# cslr_edma3cc register map
Vendor: Texas Instruments
Peripheral module from a debugger description file.
Registers are 32-bit, read-write, reset 0x0 unless marked. A register's access mark holds for its fields unless they carry their own. Offsets are as the file gives them; lines under a group give offsets from that group; [hi:lo] are bit positions; {n}, {i} and the like mark numbered series; 'fields as' and 'values as' point back to an identical list; <NAME> marks a mode.

## EDMA3CC — Enhanced DMA Channel Controller Module.
0x00 PID ro — Peripheral Revision
  [31:0] REG
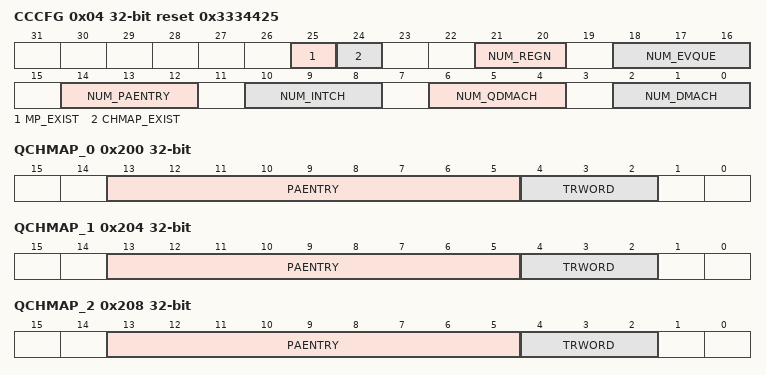
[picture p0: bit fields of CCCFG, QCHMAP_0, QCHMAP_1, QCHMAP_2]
0x04 CCCFG ro reset 0x3334425 — CC Configuration
  [25] MP_EXIST — Memory Protection Existence
    1=INCLUDED (Memory protection logic included)
  [24] CHMAP_EXIST — Channel Mapping Existence
    1=INCLUDED (Channel mapping logic included)
  [21:20] NUM_REGN — Number of MP and Shadow regions
    3=8 Regions
  [18:16] NUM_EVQUE — Number of Queues/Number of TCs
    3=4 TC/Event Queue
  [14:12] NUM_PAENTRY — Number of PaRAM entries
    4=256 Entries
  [10:8] NUM_INTCH — Number of Interrupt Channels
    4=64 Interrupt Channels
  [6:4] NUM_QDMACH — Number of QDMA Channels
    2=4 QDMA Channels
  [2:0] NUM_DMACH — Number of DMA Channels
    5=64 DMA Channels
0x100 DCHMAP_0 access per field — DMA Channel Mapping to PaRAM{DCHMAP}
  [13:5] PAENTRY rw — Points to the PaRAM Entry number for the DMA Channel N
0x104 DCHMAP_1 access per field — DMA Channel Mapping to PaRAM{DCHMAP}
  fields as DCHMAP_0
0x108 DCHMAP_2 access per field — DMA Channel Mapping to PaRAM{DCHMAP}
  fields as DCHMAP_0
0x10C DCHMAP_3 access per field — DMA Channel Mapping to PaRAM{DCHMAP}
  fields as DCHMAP_0
0x110 DCHMAP_4 access per field — DMA Channel Mapping to PaRAM{DCHMAP}
  fields as DCHMAP_0
0x114 DCHMAP_5 access per field — DMA Channel Mapping to PaRAM{DCHMAP}
  fields as DCHMAP_0
0x118 DCHMAP_6 access per field — DMA Channel Mapping to PaRAM{DCHMAP}
  fields as DCHMAP_0
0x11C DCHMAP_7 access per field — DMA Channel Mapping to PaRAM{DCHMAP}
  fields as DCHMAP_0
0x120 DCHMAP_8 access per field — DMA Channel Mapping to PaRAM{DCHMAP}
  fields as DCHMAP_0
0x124 DCHMAP_9 access per field — DMA Channel Mapping to PaRAM{DCHMAP}
  fields as DCHMAP_0
0x128 DCHMAP_10 access per field — DMA Channel Mapping to PaRAM{DCHMAP}
  fields as DCHMAP_0
0x12C DCHMAP_11 access per field — DMA Channel Mapping to PaRAM{DCHMAP}
  fields as DCHMAP_0
0x130 DCHMAP_12 access per field — DMA Channel Mapping to PaRAM{DCHMAP}
  fields as DCHMAP_0
0x134 DCHMAP_13 access per field — DMA Channel Mapping to PaRAM{DCHMAP}
  fields as DCHMAP_0
0x138 DCHMAP_14 access per field — DMA Channel Mapping to PaRAM{DCHMAP}
  fields as DCHMAP_0
0x13C DCHMAP_15 access per field — DMA Channel Mapping to PaRAM{DCHMAP}
  fields as DCHMAP_0
0x140 DCHMAP_16 access per field — DMA Channel Mapping to PaRAM{DCHMAP}
  fields as DCHMAP_0
0x144 DCHMAP_17 access per field — DMA Channel Mapping to PaRAM{DCHMAP}
  fields as DCHMAP_0
0x148 DCHMAP_18 access per field — DMA Channel Mapping to PaRAM{DCHMAP}
  fields as DCHMAP_0
0x14C DCHMAP_19 access per field — DMA Channel Mapping to PaRAM{DCHMAP}
  fields as DCHMAP_0
0x150 DCHMAP_20 access per field — DMA Channel Mapping to PaRAM{DCHMAP}
  fields as DCHMAP_0
0x154 DCHMAP_21 access per field — DMA Channel Mapping to PaRAM{DCHMAP}
  fields as DCHMAP_0
0x158 DCHMAP_22 access per field — DMA Channel Mapping to PaRAM{DCHMAP}
  fields as DCHMAP_0
0x15C DCHMAP_23 access per field — DMA Channel Mapping to PaRAM{DCHMAP}
  fields as DCHMAP_0
0x160 DCHMAP_24 access per field — DMA Channel Mapping to PaRAM{DCHMAP}
  fields as DCHMAP_0
0x164 DCHMAP_25 access per field — DMA Channel Mapping to PaRAM{DCHMAP}
  fields as DCHMAP_0
0x168 DCHMAP_26 access per field — DMA Channel Mapping to PaRAM{DCHMAP}
  fields as DCHMAP_0
0x16C DCHMAP_27 access per field — DMA Channel Mapping to PaRAM{DCHMAP}
  fields as DCHMAP_0
0x170 DCHMAP_28 access per field — DMA Channel Mapping to PaRAM{DCHMAP}
  fields as DCHMAP_0
0x174 DCHMAP_29 access per field — DMA Channel Mapping to PaRAM{DCHMAP}
  fields as DCHMAP_0
0x178 DCHMAP_30 access per field — DMA Channel Mapping to PaRAM{DCHMAP}
  fields as DCHMAP_0
0x17C DCHMAP_31 access per field — DMA Channel Mapping to PaRAM{DCHMAP}
  fields as DCHMAP_0
0x180 DCHMAP_32 access per field — DMA Channel Mapping to PaRAM{DCHMAP}
  fields as DCHMAP_0
0x184 DCHMAP_33 access per field — DMA Channel Mapping to PaRAM{DCHMAP}
  fields as DCHMAP_0
0x188 DCHMAP_34 access per field — DMA Channel Mapping to PaRAM{DCHMAP}
  fields as DCHMAP_0
0x18C DCHMAP_35 access per field — DMA Channel Mapping to PaRAM{DCHMAP}
  fields as DCHMAP_0
0x190 DCHMAP_36 access per field — DMA Channel Mapping to PaRAM{DCHMAP}
  fields as DCHMAP_0
0x194 DCHMAP_37 access per field — DMA Channel Mapping to PaRAM{DCHMAP}
  fields as DCHMAP_0
0x198 DCHMAP_38 access per field — DMA Channel Mapping to PaRAM{DCHMAP}
  fields as DCHMAP_0
0x19C DCHMAP_39 access per field — DMA Channel Mapping to PaRAM{DCHMAP}
  fields as DCHMAP_0
0x1A0 DCHMAP_40 access per field — DMA Channel Mapping to PaRAM{DCHMAP}
  fields as DCHMAP_0
0x1A4 DCHMAP_41 access per field — DMA Channel Mapping to PaRAM{DCHMAP}
  fields as DCHMAP_0
0x1A8 DCHMAP_42 access per field — DMA Channel Mapping to PaRAM{DCHMAP}
  fields as DCHMAP_0
0x1AC DCHMAP_43 access per field — DMA Channel Mapping to PaRAM{DCHMAP}
  fields as DCHMAP_0
0x1B0 DCHMAP_44 access per field — DMA Channel Mapping to PaRAM{DCHMAP}
  fields as DCHMAP_0
0x1B4 DCHMAP_45 access per field — DMA Channel Mapping to PaRAM{DCHMAP}
  fields as DCHMAP_0
0x1B8 DCHMAP_46 access per field — DMA Channel Mapping to PaRAM{DCHMAP}
  fields as DCHMAP_0
0x1BC DCHMAP_47 access per field — DMA Channel Mapping to PaRAM{DCHMAP}
  fields as DCHMAP_0
0x1C0 DCHMAP_48 access per field — DMA Channel Mapping to PaRAM{DCHMAP}
  fields as DCHMAP_0
0x1C4 DCHMAP_49 access per field — DMA Channel Mapping to PaRAM{DCHMAP}
  fields as DCHMAP_0
0x1C8 DCHMAP_50 access per field — DMA Channel Mapping to PaRAM{DCHMAP}
  fields as DCHMAP_0
0x1CC DCHMAP_51 access per field — DMA Channel Mapping to PaRAM{DCHMAP}
  fields as DCHMAP_0
0x1D0 DCHMAP_52 access per field — DMA Channel Mapping to PaRAM{DCHMAP}
  fields as DCHMAP_0
0x1D4 DCHMAP_53 access per field — DMA Channel Mapping to PaRAM{DCHMAP}
  fields as DCHMAP_0
0x1D8 DCHMAP_54 access per field — DMA Channel Mapping to PaRAM{DCHMAP}
  fields as DCHMAP_0
0x1DC DCHMAP_55 access per field — DMA Channel Mapping to PaRAM{DCHMAP}
  fields as DCHMAP_0
0x1E0 DCHMAP_56 access per field — DMA Channel Mapping to PaRAM{DCHMAP}
  fields as DCHMAP_0
0x1E4 DCHMAP_57 access per field — DMA Channel Mapping to PaRAM{DCHMAP}
  fields as DCHMAP_0
0x1E8 DCHMAP_58 access per field — DMA Channel Mapping to PaRAM{DCHMAP}
  fields as DCHMAP_0
0x1EC DCHMAP_59 access per field — DMA Channel Mapping to PaRAM{DCHMAP}
  fields as DCHMAP_0
0x1F0 DCHMAP_60 access per field — DMA Channel Mapping to PaRAM{DCHMAP}
  fields as DCHMAP_0
0x1F4 DCHMAP_61 access per field — DMA Channel Mapping to PaRAM{DCHMAP}
  fields as DCHMAP_0
0x1F8 DCHMAP_62 access per field — DMA Channel Mapping to PaRAM{DCHMAP}
  fields as DCHMAP_0
0x1FC DCHMAP_63 access per field — DMA Channel Mapping to PaRAM{DCHMAP}
  fields as DCHMAP_0
0x200 QCHMAP_0 access per field — QDMA Channel Mapping to PaRAM{QCHMAP}
  [13:5] PAENTRY rw — Points to the PaRAM Entry number for the DMA Channel N
  [4:2] TRWORD rw — Points to the specific trigger word of the PaRAM entry defined by PAENTRY
0x204 QCHMAP_1 access per field — QDMA Channel Mapping to PaRAM{QCHMAP}
  fields as QCHMAP_0
0x208 QCHMAP_2 access per field — QDMA Channel Mapping to PaRAM{QCHMAP}
  fields as QCHMAP_0
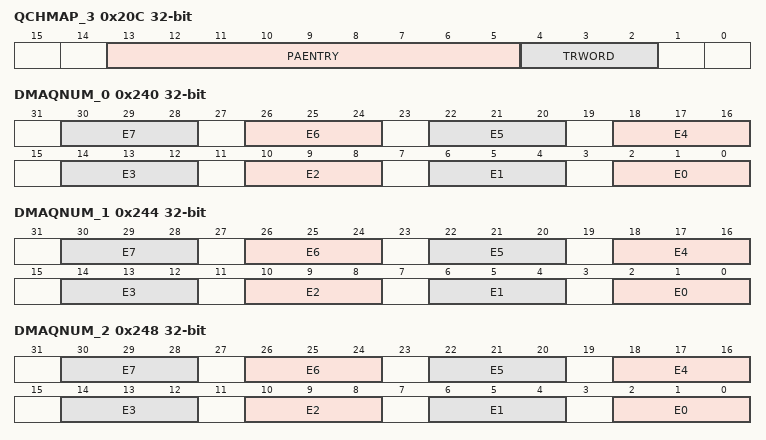
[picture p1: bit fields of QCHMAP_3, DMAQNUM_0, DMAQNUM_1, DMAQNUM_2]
0x20C QCHMAP_3 access per field — QDMA Channel Mapping to PaRAM{QCHMAP}
  fields as QCHMAP_0
0x240 DMAQNUM_0 access per field — DMA Queue Number{DMAQNUM}
  [4n+2:4n] E{n} rw (n=0..7) — Event number = (ArrayIndex * 8) + {n}
0x244 DMAQNUM_1 access per field — DMA Queue Number{DMAQNUM}
  [4n+2:4n] E{n} rw (n=0..7) — Event number = (ArrayIndex * 8) + {n}
0x248 DMAQNUM_2 access per field — DMA Queue Number{DMAQNUM}
  [4n+2:4n] E{n} rw (n=0..7) — Event number = (ArrayIndex * 8) + {n}
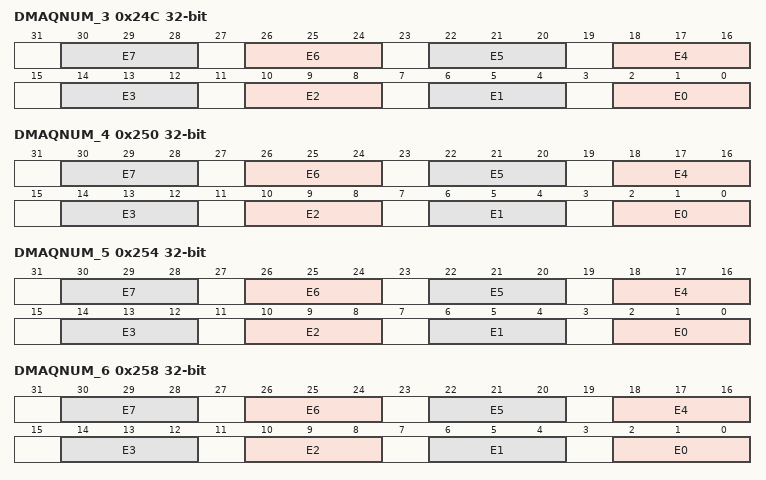
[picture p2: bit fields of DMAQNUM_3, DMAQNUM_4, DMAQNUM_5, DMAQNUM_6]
0x24C DMAQNUM_3 access per field — DMA Queue Number{DMAQNUM}
  [4n+2:4n] E{n} rw (n=0..7) — Event number = (ArrayIndex * 8) + {n}
0x250 DMAQNUM_4 access per field — DMA Queue Number{DMAQNUM}
  [4n+2:4n] E{n} rw (n=0..7) — Event number = (ArrayIndex * 8) + {n}
0x254 DMAQNUM_5 access per field — DMA Queue Number{DMAQNUM}
  [4n+2:4n] E{n} rw (n=0..7) — Event number = (ArrayIndex * 8) + {n}
0x258 DMAQNUM_6 access per field — DMA Queue Number{DMAQNUM}
  [4n+2:4n] E{n} rw (n=0..7) — Event number = (ArrayIndex * 8) + {n}
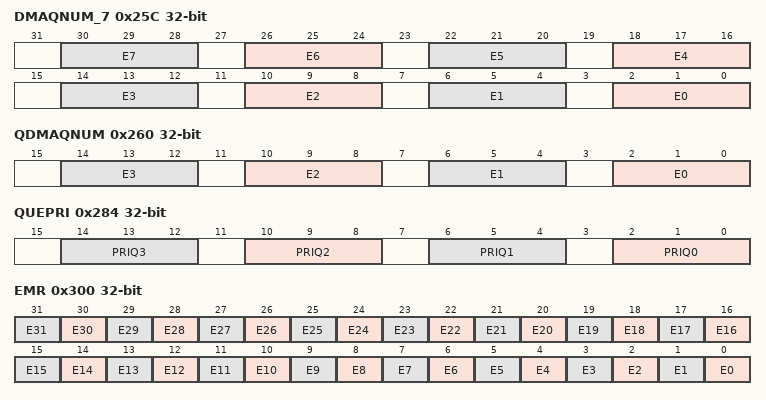
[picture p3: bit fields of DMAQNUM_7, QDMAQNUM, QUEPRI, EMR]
0x25C DMAQNUM_7 access per field — DMA Queue Number{DMAQNUM}
  [4n+2:4n] E{n} rw (n=0..7) — Event number = (ArrayIndex * 8) + {n}
0x260 QDMAQNUM access per field — QDMA Queue Number
  [4n+2:4n] E{n} rw (n=0..3) — Event number {n}
0x284 QUEPRI access per field — Queue Priority
  [4n+2:4n] PRIQ{n} rw (n=0..3) — Priority level for Queue {n}
0x300 EMR ro — Event Miss Register
  [n] E{n} (n=0..31) — Event missed number {n}
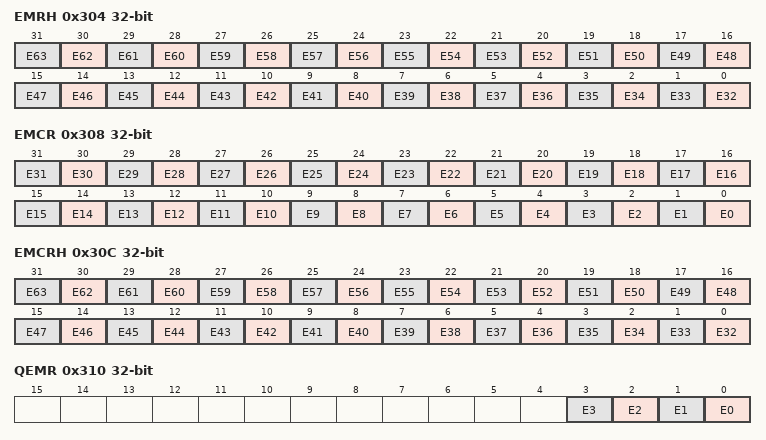
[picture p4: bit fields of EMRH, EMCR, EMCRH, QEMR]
0x304 EMRH ro — Event Miss Register High
  [n-32] E{n} (n=32..63) — Event missed number {n}
0x308 EMCR wo — Event Miss Clear Register
  [all] fields
    1=CLEAR
  [n] E{n} (n=0..31) — Event missed number {n}
0x30C EMCRH wo — Event Miss Clear Register High
  [all] fields
    1=CLEAR
  [n-32] E{n} (n=32..63) — Event missed number {n}
0x310 QEMR ro — QDMA Event Miss Register
  [n] E{n} (n=0..3) — Event miss event {n}
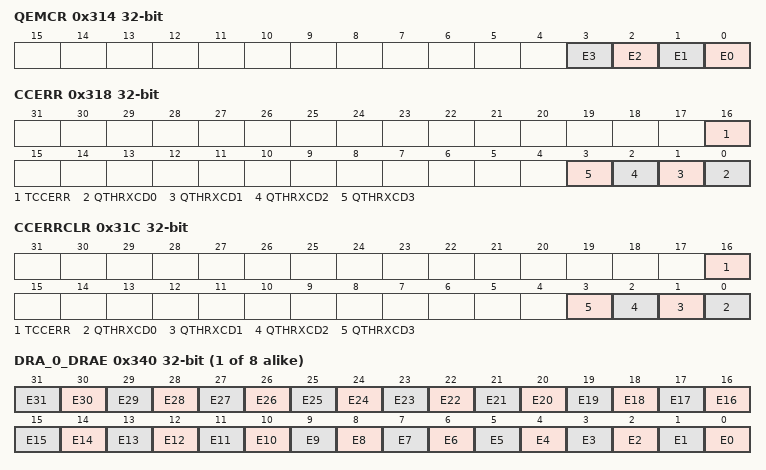
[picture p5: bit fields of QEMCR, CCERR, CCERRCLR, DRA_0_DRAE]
0x314 QEMCR wo — QDMA Event Miss Register
  [all] fields
    1=CLEAR
  [n] E{n} (n=0..3) — Event miss event {n}
0x318 CCERR ro — CC Error Register
  [16] TCCERR — Transfer completion code error
  [n] QTHRXCD{n} (n=0..3) — Queue Threshold Error for Queue {n}
0x31C CCERRCLR wo — CC Error Clear Register
  [all] fields
    1=CLEAR
  [16] TCCERR — Transfer completion code error
  [n] QTHRXCD{n} (n=0..3) — Queue Threshold Error for Queue {n}
0x320 EEVAL access per field — Error Evaluation Register
  [0] EVAL wo — Error interrupt Evaluate
    1=EVAL (Error Interrupt Evaluate)
{0x340+8i} DRA_{i}_DRAE (i=0..7) — DMA Region Access Enable
  [n] E{n} (n=0..31) — Event missed number {n}
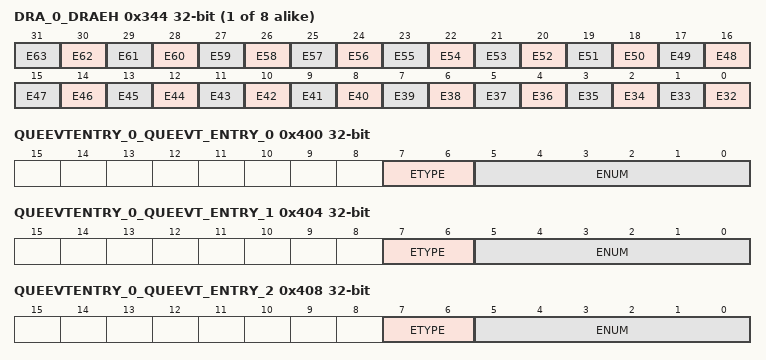
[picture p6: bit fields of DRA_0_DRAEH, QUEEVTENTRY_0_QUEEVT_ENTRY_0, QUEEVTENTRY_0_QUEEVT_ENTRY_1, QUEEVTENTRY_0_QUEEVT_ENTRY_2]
{0x344+8i} DRA_{i}_DRAEH (i=0..7) — DMA Region Access Enable High
  [n-32] E{n} (n=32..63) — Event missed number {n}
0x380 QRAE_0 access not given — QDMA Region Access Enable{QRAE}
  [7] E{n} rw (n=0..7) — QDMA Register bit {n}
  [6:0] Reserved — (access N)
0x384 QRAE_1 access not given — QDMA Region Access Enable{QRAE}
  fields as QRAE_0
0x388 QRAE_2 access not given — QDMA Region Access Enable{QRAE}
  fields as QRAE_0
0x38C QRAE_3 access not given — QDMA Region Access Enable{QRAE}
  fields as QRAE_0
0x390 QRAE_4 access not given — QDMA Region Access Enable{QRAE}
  fields as QRAE_0
0x394 QRAE_5 access not given — QDMA Region Access Enable{QRAE}
  fields as QRAE_0
0x398 QRAE_6 access not given — QDMA Region Access Enable{QRAE}
  fields as QRAE_0
0x39C QRAE_7 access not given — QDMA Region Access Enable{QRAE}
  fields as QRAE_0
0x400 QUEEVTENTRY_0_QUEEVT_ENTRY_0 ro — Event Entry{EVT_ENTRY}
  [7:6] ETYPE — Event Type
    0=EVENT (Event Triggered via ER); 1=MANUAL (Manual Triggered via ESR); 2=CHAIN (Chain Triggered via CER); 3=AUTO (Auto Triggered via QER)
  [5:0] ENUM — Event Number (0-63)/(0-3)
0x404 QUEEVTENTRY_0_QUEEVT_ENTRY_1 ro — Event Entry{EVT_ENTRY}
  fields as QUEEVTENTRY_0_QUEEVT_ENTRY_0
0x408 QUEEVTENTRY_0_QUEEVT_ENTRY_2 ro — Event Entry{EVT_ENTRY}
  fields as QUEEVTENTRY_0_QUEEVT_ENTRY_0
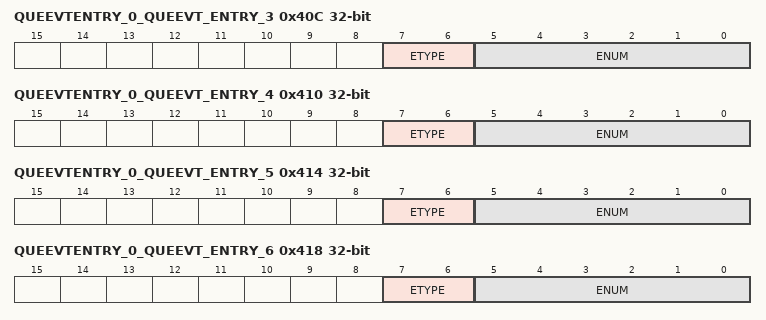
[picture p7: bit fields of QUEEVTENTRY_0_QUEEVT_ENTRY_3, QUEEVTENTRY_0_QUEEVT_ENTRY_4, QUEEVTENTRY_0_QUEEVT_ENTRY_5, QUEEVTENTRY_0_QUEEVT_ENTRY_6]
0x40C QUEEVTENTRY_0_QUEEVT_ENTRY_3 ro — Event Entry{EVT_ENTRY}
  fields as QUEEVTENTRY_0_QUEEVT_ENTRY_0
0x410 QUEEVTENTRY_0_QUEEVT_ENTRY_4 ro — Event Entry{EVT_ENTRY}
  fields as QUEEVTENTRY_0_QUEEVT_ENTRY_0
0x414 QUEEVTENTRY_0_QUEEVT_ENTRY_5 ro — Event Entry{EVT_ENTRY}
  fields as QUEEVTENTRY_0_QUEEVT_ENTRY_0
0x418 QUEEVTENTRY_0_QUEEVT_ENTRY_6 ro — Event Entry{EVT_ENTRY}
  fields as QUEEVTENTRY_0_QUEEVT_ENTRY_0
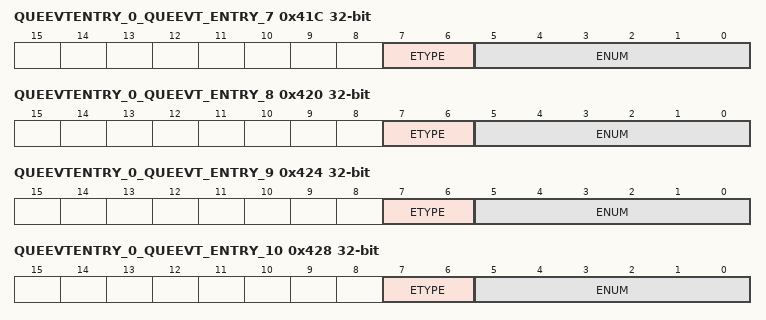
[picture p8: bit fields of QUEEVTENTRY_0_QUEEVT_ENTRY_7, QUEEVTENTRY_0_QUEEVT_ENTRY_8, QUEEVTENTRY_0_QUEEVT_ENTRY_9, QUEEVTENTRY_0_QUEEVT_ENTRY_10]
0x41C QUEEVTENTRY_0_QUEEVT_ENTRY_7 ro — Event Entry{EVT_ENTRY}
  fields as QUEEVTENTRY_0_QUEEVT_ENTRY_0
0x420 QUEEVTENTRY_0_QUEEVT_ENTRY_8 ro — Event Entry{EVT_ENTRY}
  fields as QUEEVTENTRY_0_QUEEVT_ENTRY_0
0x424 QUEEVTENTRY_0_QUEEVT_ENTRY_9 ro — Event Entry{EVT_ENTRY}
  fields as QUEEVTENTRY_0_QUEEVT_ENTRY_0
0x428 QUEEVTENTRY_0_QUEEVT_ENTRY_10 ro — Event Entry{EVT_ENTRY}
  fields as QUEEVTENTRY_0_QUEEVT_ENTRY_0
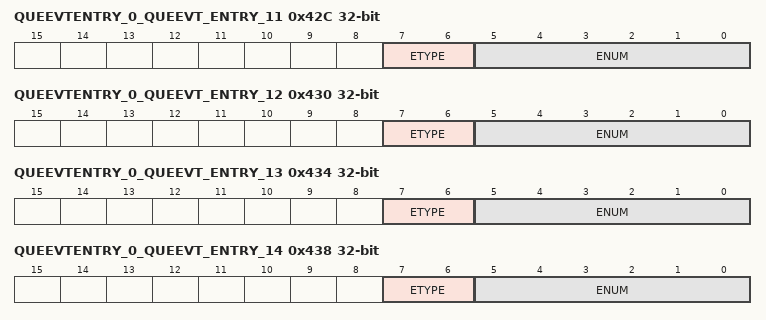
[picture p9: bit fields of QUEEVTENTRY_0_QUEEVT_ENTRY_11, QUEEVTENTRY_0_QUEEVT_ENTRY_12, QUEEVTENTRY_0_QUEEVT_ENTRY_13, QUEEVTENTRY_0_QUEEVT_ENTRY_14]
0x42C QUEEVTENTRY_0_QUEEVT_ENTRY_11 ro — Event Entry{EVT_ENTRY}
  fields as QUEEVTENTRY_0_QUEEVT_ENTRY_0
0x430 QUEEVTENTRY_0_QUEEVT_ENTRY_12 ro — Event Entry{EVT_ENTRY}
  fields as QUEEVTENTRY_0_QUEEVT_ENTRY_0
0x434 QUEEVTENTRY_0_QUEEVT_ENTRY_13 ro — Event Entry{EVT_ENTRY}
  fields as QUEEVTENTRY_0_QUEEVT_ENTRY_0
0x438 QUEEVTENTRY_0_QUEEVT_ENTRY_14 ro — Event Entry{EVT_ENTRY}
  fields as QUEEVTENTRY_0_QUEEVT_ENTRY_0
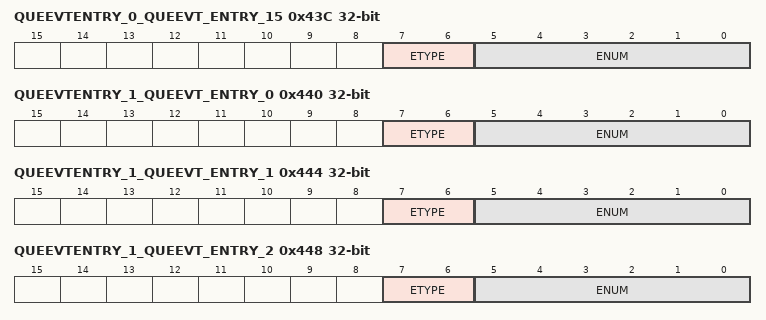
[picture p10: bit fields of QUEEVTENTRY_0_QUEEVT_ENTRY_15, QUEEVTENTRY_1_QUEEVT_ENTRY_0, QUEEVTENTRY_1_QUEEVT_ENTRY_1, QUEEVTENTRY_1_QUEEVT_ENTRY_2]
0x43C QUEEVTENTRY_0_QUEEVT_ENTRY_15 ro — Event Entry{EVT_ENTRY}
  fields as QUEEVTENTRY_0_QUEEVT_ENTRY_0
0x440 QUEEVTENTRY_1_QUEEVT_ENTRY_0 ro — Event Entry{EVT_ENTRY}
  fields as QUEEVTENTRY_0_QUEEVT_ENTRY_0
0x444 QUEEVTENTRY_1_QUEEVT_ENTRY_1 ro — Event Entry{EVT_ENTRY}
  fields as QUEEVTENTRY_0_QUEEVT_ENTRY_0
0x448 QUEEVTENTRY_1_QUEEVT_ENTRY_2 ro — Event Entry{EVT_ENTRY}
  fields as QUEEVTENTRY_0_QUEEVT_ENTRY_0
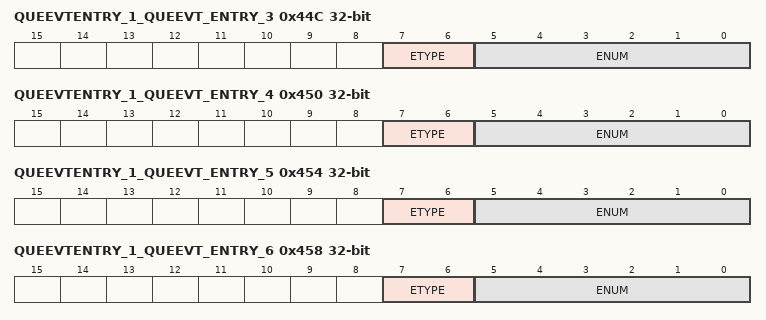
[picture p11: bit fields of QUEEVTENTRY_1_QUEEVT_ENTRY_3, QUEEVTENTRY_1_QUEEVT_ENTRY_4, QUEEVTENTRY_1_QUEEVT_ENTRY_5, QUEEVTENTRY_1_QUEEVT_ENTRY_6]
0x44C QUEEVTENTRY_1_QUEEVT_ENTRY_3 ro — Event Entry{EVT_ENTRY}
  fields as QUEEVTENTRY_0_QUEEVT_ENTRY_0
0x450 QUEEVTENTRY_1_QUEEVT_ENTRY_4 ro — Event Entry{EVT_ENTRY}
  fields as QUEEVTENTRY_0_QUEEVT_ENTRY_0
0x454 QUEEVTENTRY_1_QUEEVT_ENTRY_5 ro — Event Entry{EVT_ENTRY}
  fields as QUEEVTENTRY_0_QUEEVT_ENTRY_0
0x458 QUEEVTENTRY_1_QUEEVT_ENTRY_6 ro — Event Entry{EVT_ENTRY}
  fields as QUEEVTENTRY_0_QUEEVT_ENTRY_0
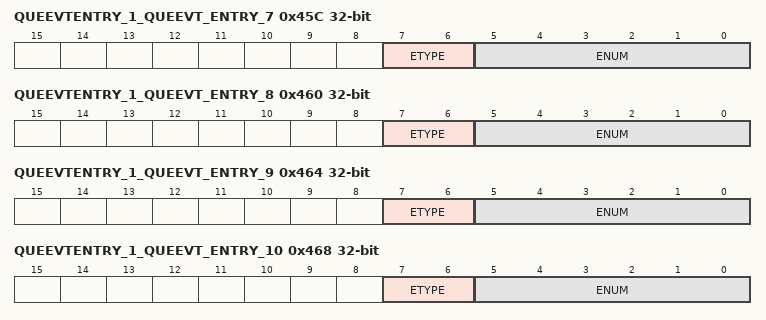
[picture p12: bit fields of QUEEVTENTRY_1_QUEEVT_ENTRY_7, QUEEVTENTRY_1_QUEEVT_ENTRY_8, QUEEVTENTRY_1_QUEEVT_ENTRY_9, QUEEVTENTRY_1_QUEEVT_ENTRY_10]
0x45C QUEEVTENTRY_1_QUEEVT_ENTRY_7 ro — Event Entry{EVT_ENTRY}
  fields as QUEEVTENTRY_0_QUEEVT_ENTRY_0
0x460 QUEEVTENTRY_1_QUEEVT_ENTRY_8 ro — Event Entry{EVT_ENTRY}
  fields as QUEEVTENTRY_0_QUEEVT_ENTRY_0
0x464 QUEEVTENTRY_1_QUEEVT_ENTRY_9 ro — Event Entry{EVT_ENTRY}
  fields as QUEEVTENTRY_0_QUEEVT_ENTRY_0
0x468 QUEEVTENTRY_1_QUEEVT_ENTRY_10 ro — Event Entry{EVT_ENTRY}
  fields as QUEEVTENTRY_0_QUEEVT_ENTRY_0
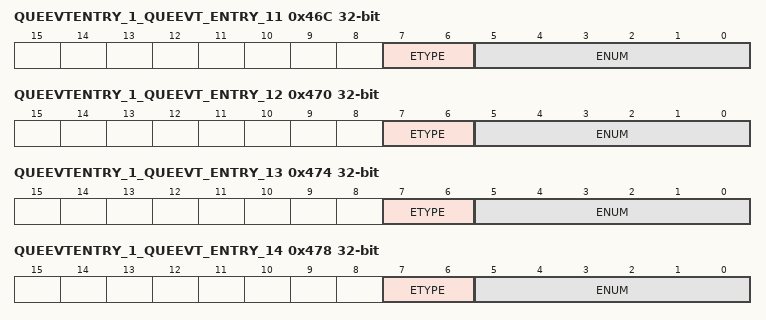
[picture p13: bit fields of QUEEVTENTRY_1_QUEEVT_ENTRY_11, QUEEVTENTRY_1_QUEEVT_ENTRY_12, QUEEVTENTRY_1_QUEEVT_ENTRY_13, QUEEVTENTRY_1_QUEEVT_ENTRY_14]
0x46C QUEEVTENTRY_1_QUEEVT_ENTRY_11 ro — Event Entry{EVT_ENTRY}
  fields as QUEEVTENTRY_0_QUEEVT_ENTRY_0
0x470 QUEEVTENTRY_1_QUEEVT_ENTRY_12 ro — Event Entry{EVT_ENTRY}
  fields as QUEEVTENTRY_0_QUEEVT_ENTRY_0
0x474 QUEEVTENTRY_1_QUEEVT_ENTRY_13 ro — Event Entry{EVT_ENTRY}
  fields as QUEEVTENTRY_0_QUEEVT_ENTRY_0
0x478 QUEEVTENTRY_1_QUEEVT_ENTRY_14 ro — Event Entry{EVT_ENTRY}
  fields as QUEEVTENTRY_0_QUEEVT_ENTRY_0
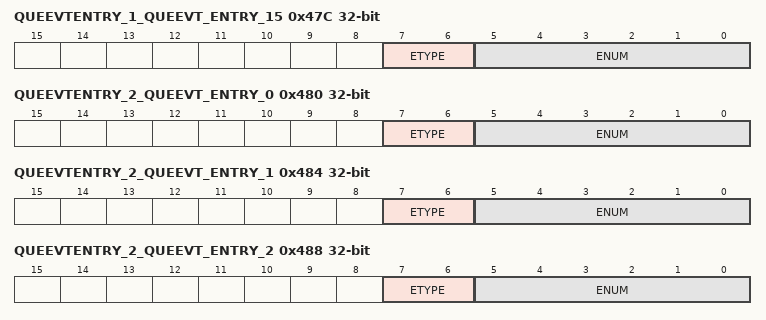
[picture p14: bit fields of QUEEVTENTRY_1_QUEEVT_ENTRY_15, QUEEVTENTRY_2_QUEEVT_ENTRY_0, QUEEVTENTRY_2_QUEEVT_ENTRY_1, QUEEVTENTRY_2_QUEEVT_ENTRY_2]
0x47C QUEEVTENTRY_1_QUEEVT_ENTRY_15 ro — Event Entry{EVT_ENTRY}
  fields as QUEEVTENTRY_0_QUEEVT_ENTRY_0
0x480 QUEEVTENTRY_2_QUEEVT_ENTRY_0 ro — Event Entry{EVT_ENTRY}
  fields as QUEEVTENTRY_0_QUEEVT_ENTRY_0
0x484 QUEEVTENTRY_2_QUEEVT_ENTRY_1 ro — Event Entry{EVT_ENTRY}
  fields as QUEEVTENTRY_0_QUEEVT_ENTRY_0
0x488 QUEEVTENTRY_2_QUEEVT_ENTRY_2 ro — Event Entry{EVT_ENTRY}
  fields as QUEEVTENTRY_0_QUEEVT_ENTRY_0
0x48C QUEEVTENTRY_2_QUEEVT_ENTRY_3 ro — Event Entry{EVT_ENTRY}
  fields as QUEEVTENTRY_0_QUEEVT_ENTRY_0
0x490 QUEEVTENTRY_2_QUEEVT_ENTRY_4 ro — Event Entry{EVT_ENTRY}
  fields as QUEEVTENTRY_0_QUEEVT_ENTRY_0
0x494 QUEEVTENTRY_2_QUEEVT_ENTRY_5 ro — Event Entry{EVT_ENTRY}
  fields as QUEEVTENTRY_0_QUEEVT_ENTRY_0
0x498 QUEEVTENTRY_2_QUEEVT_ENTRY_6 ro — Event Entry{EVT_ENTRY}
  fields as QUEEVTENTRY_0_QUEEVT_ENTRY_0
0x49C QUEEVTENTRY_2_QUEEVT_ENTRY_7 ro — Event Entry{EVT_ENTRY}
  fields as QUEEVTENTRY_0_QUEEVT_ENTRY_0
0x4A0 QUEEVTENTRY_2_QUEEVT_ENTRY_8 ro — Event Entry{EVT_ENTRY}
  fields as QUEEVTENTRY_0_QUEEVT_ENTRY_0
0x4A4 QUEEVTENTRY_2_QUEEVT_ENTRY_9 ro — Event Entry{EVT_ENTRY}
  fields as QUEEVTENTRY_0_QUEEVT_ENTRY_0
0x4A8 QUEEVTENTRY_2_QUEEVT_ENTRY_10 ro — Event Entry{EVT_ENTRY}
  fields as QUEEVTENTRY_0_QUEEVT_ENTRY_0
0x4AC QUEEVTENTRY_2_QUEEVT_ENTRY_11 ro — Event Entry{EVT_ENTRY}
  fields as QUEEVTENTRY_0_QUEEVT_ENTRY_0
0x4B0 QUEEVTENTRY_2_QUEEVT_ENTRY_12 ro — Event Entry{EVT_ENTRY}
  fields as QUEEVTENTRY_0_QUEEVT_ENTRY_0
0x4B4 QUEEVTENTRY_2_QUEEVT_ENTRY_13 ro — Event Entry{EVT_ENTRY}
  fields as QUEEVTENTRY_0_QUEEVT_ENTRY_0
0x4B8 QUEEVTENTRY_2_QUEEVT_ENTRY_14 ro — Event Entry{EVT_ENTRY}
  fields as QUEEVTENTRY_0_QUEEVT_ENTRY_0
0x4BC QUEEVTENTRY_2_QUEEVT_ENTRY_15 ro — Event Entry{EVT_ENTRY}
  fields as QUEEVTENTRY_0_QUEEVT_ENTRY_0
0x4C0 QUEEVTENTRY_3_QUEEVT_ENTRY_0 ro — Event Entry{EVT_ENTRY}
  fields as QUEEVTENTRY_0_QUEEVT_ENTRY_0
0x4C4 QUEEVTENTRY_3_QUEEVT_ENTRY_1 ro — Event Entry{EVT_ENTRY}
  fields as QUEEVTENTRY_0_QUEEVT_ENTRY_0
0x4C8 QUEEVTENTRY_3_QUEEVT_ENTRY_2 ro — Event Entry{EVT_ENTRY}
  fields as QUEEVTENTRY_0_QUEEVT_ENTRY_0
0x4CC QUEEVTENTRY_3_QUEEVT_ENTRY_3 ro — Event Entry{EVT_ENTRY}
  fields as QUEEVTENTRY_0_QUEEVT_ENTRY_0
0x4D0 QUEEVTENTRY_3_QUEEVT_ENTRY_4 ro — Event Entry{EVT_ENTRY}
  fields as QUEEVTENTRY_0_QUEEVT_ENTRY_0
0x4D4 QUEEVTENTRY_3_QUEEVT_ENTRY_5 ro — Event Entry{EVT_ENTRY}
  fields as QUEEVTENTRY_0_QUEEVT_ENTRY_0
0x4D8 QUEEVTENTRY_3_QUEEVT_ENTRY_6 ro — Event Entry{EVT_ENTRY}
  fields as QUEEVTENTRY_0_QUEEVT_ENTRY_0
0x4DC QUEEVTENTRY_3_QUEEVT_ENTRY_7 ro — Event Entry{EVT_ENTRY}
  fields as QUEEVTENTRY_0_QUEEVT_ENTRY_0
0x4E0 QUEEVTENTRY_3_QUEEVT_ENTRY_8 ro — Event Entry{EVT_ENTRY}
  fields as QUEEVTENTRY_0_QUEEVT_ENTRY_0
0x4E4 QUEEVTENTRY_3_QUEEVT_ENTRY_9 ro — Event Entry{EVT_ENTRY}
  fields as QUEEVTENTRY_0_QUEEVT_ENTRY_0
0x4E8 QUEEVTENTRY_3_QUEEVT_ENTRY_10 ro — Event Entry{EVT_ENTRY}
  fields as QUEEVTENTRY_0_QUEEVT_ENTRY_0
0x4EC QUEEVTENTRY_3_QUEEVT_ENTRY_11 ro — Event Entry{EVT_ENTRY}
  fields as QUEEVTENTRY_0_QUEEVT_ENTRY_0
0x4F0 QUEEVTENTRY_3_QUEEVT_ENTRY_12 ro — Event Entry{EVT_ENTRY}
  fields as QUEEVTENTRY_0_QUEEVT_ENTRY_0
0x4F4 QUEEVTENTRY_3_QUEEVT_ENTRY_13 ro — Event Entry{EVT_ENTRY}
  fields as QUEEVTENTRY_0_QUEEVT_ENTRY_0
0x4F8 QUEEVTENTRY_3_QUEEVT_ENTRY_14 ro — Event Entry{EVT_ENTRY}
  fields as QUEEVTENTRY_0_QUEEVT_ENTRY_0
0x4FC QUEEVTENTRY_3_QUEEVT_ENTRY_15 ro — Event Entry{EVT_ENTRY}
  fields as QUEEVTENTRY_0_QUEEVT_ENTRY_0
0x600 QSTAT_0 access not given — Queue Status{QSTAT}
  [24] THRXD ro — Threshold Exceeded
    0=NOTEXCEED (Not Exceeded); 1=EXCEED (Exceeded)
  [22:21] Reserved — (access N)
  [20:16] WM ro — Watermark for Maximum Queue Usage
    0=EMPTY (Empty Queue); 22=FULL (Full Queue)
  [12:8] NUMVAL ro — Number of Valid Entries in Queue
  [3:0] STRTPTR ro — Start Pointer
0x604 QSTAT_1 access not given — Queue Status{QSTAT}
  fields as QSTAT_0
0x608 QSTAT_2 access not given — Queue Status{QSTAT}
  fields as QSTAT_0
0x60C QSTAT_3 access not given — Queue Status{QSTAT}
  fields as QSTAT_0
0x620 QWMTHRA access per field reset 0x10101010 — Queue Threshold A
  [all] fields
    23=DISABLE (Disable threshold errors)
  [8n+4:8n] Q{n} rw (n=0..3) — Q{n} Threshold
0x640 CCSTAT ro — Channel Controller Status
  [n+16] QUEACTV{n} (n=0..3) — Queue {n} Active
    0=NONE; 1=ACTIVE
  [13:8] COMPACTV — Completion Request Active
    0=NONE
  [4] ACTV — Channel Controller Active
    0=IDLE; 1=BUSY
  [3] WSTATACTV — Write Status iterface Active
    0=IDLE; 1=BUSY
  [2] TRACTV — Transfer Request Active
    0=NONE; 1=ACTIVE
  [1] QEVTACTV — QDMA Event Active
    0=NONE; 1=ACTIVE
  [0] EVTACTV — DMA Event Active
    0=NONE; 1=ACTIVE
0x800 MPFAR ro — Memory Protect Fault address
  [31:0] FADDR — Fault Address
0x804 MPFSR ro reset 0x1200 — Memory Protect Fault Status
  [12:9] FID — Faulted ID
  [5] SRE — Supervisor Read Error
  [4] SWE — Supervisor Write Error
  [3] SXE — Supervisor Executer Error
  [2] URE — User Read Error
  [1] UWE — User Write Error
  [0] UXE — User Execute Error
0x808 MPFCR access per field — Memory Protect Fault Command
  [0] MPFCLR wo — Fault Clear register
0x80C MPPAG access per field reset 0xFEF6 — MP Permission attribute for Gbl Regs
  [n+10] AID{n} rw (n=0..5) — Allowed ID {n}
    0=BLOCK (Block requests with privID = {n}); 1=PERMIT (Permit requests with privID = {n})
  [9] EXT rw — External allowed ID
    0=BLOCK (Block requests with privID >= 6); 1=PERMIT (Permit requests with privID >= 6)
  [5] SR rw — Supervisor Read permissions
    0=BLOCK (Read accesses not allowed in this region); 1=PERMIT (Read accesses allowed in this region)
  [4] SW rw — Supervisor Write permissions
    0=BLOCK (Write accesses not allowed in this region); 1=PERMIT (Write accesses allowed in this region)
  [3] SX rw — Supervisor Execute permissions
    0=BLOCK (Execute accesses not allowed in this region); 1=PERMIT (Execute accesses allowed in this region)
  [2] UR rw — User Read permissions
    values as SR
  [1] UW rw — User Write permissions
    values as SW
  [0] UX rw — User Execute permissions
    values as SX
0x810 MPPA_0 access per field reset 0xFEF6 — MP Permission attribute for DMA Regs{MPPA}
  fields as MPPAG
0x814 MPPA_1 access per field reset 0xFEF6 — MP Permission attribute for DMA Regs{MPPA}
  fields as MPPAG
0x818 MPPA_2 access per field reset 0xFEF6 — MP Permission attribute for DMA Regs{MPPA}
  fields as MPPAG
0x81C MPPA_3 access per field reset 0xFEF6 — MP Permission attribute for DMA Regs{MPPA}
  fields as MPPAG
0x820 MPPA_4 access per field reset 0xFEF6 — MP Permission attribute for DMA Regs{MPPA}
  fields as MPPAG
0x824 MPPA_5 access per field reset 0xFEF6 — MP Permission attribute for DMA Regs{MPPA}
  fields as MPPAG
0x828 MPPA_6 access per field reset 0xFEF6 — MP Permission attribute for DMA Regs{MPPA}
  fields as MPPAG
0x82C MPPA_7 access per field reset 0xFEF6 — MP Permission attribute for DMA Regs{MPPA}
  fields as MPPAG
0x1000 ER ro — Event Register
  [n] E{n} (n=0..31) — Event {n}
0x1004 ERH ro — Event Register High
  [n-32] E{n} (n=32..63) — Event {n}
0x1008 ECR wo — Event Clear Register
  [all] fields
    1=CLEAR
  [n] E{n} (n=0..31) — Event {n}
0x100C ECRH wo — Event Clear Register High
  [all] fields
    1=CLEAR
  [n-32] E{n} (n=32..63) — Event {n}
0x1010 ESR wo — Event Set Register
  [all] fields
    1=SET
  [n] E{n} (n=0..31) — Event {n}
0x1014 ESRH wo — Event Set Register High
  [all] fields
    1=SET
  [n-32] E{n} (n=32..63) — Event {n}
0x1018 CER ro — Chained Event Register
  [n] E{n} (n=0..31) — Event {n}
0x101C CERH ro — Chained Event Register High
  [n-32] E{n} (n=32..63) — Event {n}
0x1020 EER ro — Event Enable Register
  [n] E{n} (n=0..31) — Event {n}
0x1024 EERH ro — Event Enable Register High
  [n-32] E{n} (n=32..63) — Event {n}
0x1028 EECR wo — Event Enable Clear Register
  [all] fields
    1=CLEAR
  [n] E{n} (n=0..31) — Event {n}
0x102C EECRH wo — Event Enable Clear Register High
  [all] fields
    1=CLEAR
  [n-32] E{n} (n=32..63) — Event {n}
0x1030 EESR wo — Event Enable Set Register
  [all] fields
    1=SET
  [n] E{n} (n=0..31) — Event {n}
0x1034 EESRH wo — Event Enable Set Register High
  [all] fields
    1=SET
  [n-32] E{n} (n=32..63) — Event {n}
0x1038 SER ro — Secondary Event Register
  [n] E{n} (n=0..31) — Event {n}
0x103C SERH ro — Secondary Event Register High
  [n-32] E{n} (n=32..63) — Event {n}
0x1040 SECR wo — Secondary Event Clear Register
  [all] fields
    1=CLEAR
  [n] E{n} (n=0..31) — Event {n}
0x1044 SECRH wo — Secondary Event Clear Register High
  [all] fields
    1=CLEAR
  [n-32] E{n} (n=32..63) — Event {n}
0x1050 IER ro — Interrupt Enable Register
  [n] I{n} (n=0..31) — Interrupt {n}
0x1054 IERH ro — Interrupt Enable Register High
  [n-32] I{n} (n=32..63) — Interrupt {n}
0x1058 IECR wo — Interrupt Enable Clear Register
  [all] fields
    1=CLEAR
  [n] I{n} (n=0..31) — Interrupt {n}
0x105C IECRH wo — Interrupt Enable Clear Register High
  [all] fields
    1=CLEAR
  [n-32] I{n} (n=32..63) — Interrupt {n}
0x1060 IESR wo — Interrupt Enable Set Register
  [all] fields
    1=SET
  [n] I{n} (n=0..31) — Interrupt {n}
0x1064 IESRH wo — Interrupt Enable Set Register High
  [all] fields
    1=SET
  [n-32] I{n} (n=32..63) — Interrupt {n}
0x1068 IPR ro — Interrupt Pending Register
  [n] I{n} (n=0..31) — Interrupt {n}
0x106C IPRH ro — Interrupt Pending Register High
  [n-32] I{n} (n=32..63) — Interrupt {n}
0x1070 ICR wo — Interrupt Clear Register
  [all] fields
    1=CLEAR
  [n] I{n} (n=0..31) — Interrupt {n}
0x1074 ICRH wo — Interrupt Clear Register High
  [all] fields
    1=CLEAR
  [n-32] I{n} (n=32..63) — Interrupt {n}
0x1078 IEVAL access per field — Interrupt Eval Register
  [0] EVAL wo — Interrupt Evaluate
    1=EVAL (Causes Completion interrupt output to be pulsed is any enabled IERn and IPRn pending)
0x1080 QER ro — QDMA Event Register
  [n] E{n} (n=0..3) — Event {n}
0x1084 QEER ro — QDMA Event Enable Register
  [n] E{n} (n=0..3) — Event {n}
0x1088 QEECR ro — QDMA Event Enable Clear Register
  [all] fields
    1=CLEAR
  [n] E{n} (n=0..3) — Event {n}
0x108C QEESR wo — QDMA Event Enable Set Register
  [all] fields
    1=SET
  [n] E{n} (n=0..3) — Event {n}
0x1090 QSER ro — QDMA Secondary Event Register
  [n] E{n} (n=0..3) — Event {n}
0x1094 QSECR access per field — QDMA Secondary Event Clear Register
  [all] fields
    1=CLEAR
  [n] E{n} wo (n=0..3) — Event {n}
{0x2000+0x200*i} SHADOW_{i}_ER ro (i=0..7) — Event Register
  [31:0] REG
{0x2004+0x200*i} SHADOW_{i}_ERH ro (i=0..7) — Event Register High
  [31:0] REG
{0x2008+0x200*i} SHADOW_{i}_ECR wo (i=0..7) — Event Clear Register
  [31:0] REG
{0x200C+0x200*i} SHADOW_{i}_ECRH wo (i=0..7) — Event Clear Register High
  [31:0] REG
{0x2010+0x200*i} SHADOW_{i}_ESR wo (i=0..7) — Event Set Register
  [31:0] REG
{0x2014+0x200*i} SHADOW_{i}_ESRH wo (i=0..7) — Event Set Register High
  [31:0] REG
{0x2018+0x200*i} SHADOW_{i}_CER ro (i=0..7) — Chained Event Register
  [31:0] REG
{0x201C+0x200*i} SHADOW_{i}_CERH ro (i=0..7) — Chained Event Register High
  [31:0] REG
{0x2020+0x200*i} SHADOW_{i}_EER ro (i=0..7) — Event Enable Register
  [31:0] REG
{0x2024+0x200*i} SHADOW_{i}_EERH ro (i=0..7) — Event Enable Register High
  [31:0] REG
{0x2028+0x200*i} SHADOW_{i}_EECR wo (i=0..7) — Event Enable Clear Register
  [31:0] REG
{0x202C+0x200*i} SHADOW_{i}_EECRH wo (i=0..7) — Event Enable Clear Register High
  [31:0] REG
{0x2030+0x200*i} SHADOW_{i}_EESR wo (i=0..7) — Event Enable Set Register
  [31:0] REG
{0x2034+0x200*i} SHADOW_{i}_EESRH wo (i=0..7) — Event Enable Set Register High
  [31:0] REG
{0x2038+0x200*i} SHADOW_{i}_SER ro (i=0..7) — Secondary Event Register
  [31:0] REG
{0x203C+0x200*i} SHADOW_{i}_SERH ro (i=0..7) — Secondary Event Register High
  [31:0] REG
{0x2040+0x200*i} SHADOW_{i}_SECR wo (i=0..7) — Secondary Event Clear Register
  [31:0] REG
{0x2044+0x200*i} SHADOW_{i}_SECRH wo (i=0..7) — Secondary Event Clear Register High
  [31:0] REG
{0x2050+0x200*i} SHADOW_{i}_IER ro (i=0..7) — Interrupt Enable Register
  [31:0] REG
{0x2054+0x200*i} SHADOW_{i}_IERH ro (i=0..7) — Interrupt Enable Register High
  [31:0] REG
{0x2058+0x200*i} SHADOW_{i}_IECR wo (i=0..7) — Interrupt Enable Clear Register
  [31:0] REG
{0x205C+0x200*i} SHADOW_{i}_IECRH wo (i=0..7) — Interrupt Enable Clear Register High
  [31:0] REG
{0x2060+0x200*i} SHADOW_{i}_IESR wo (i=0..7) — Interrupt Enable Set Register
  [31:0] REG
{0x2064+0x200*i} SHADOW_{i}_IESRH wo (i=0..7) — Interrupt Enable Set Register High
  [31:0] REG
{0x2068+0x200*i} SHADOW_{i}_IPR ro (i=0..7) — Interrupt Pending Register
  [31:0] REG
{0x206C+0x200*i} SHADOW_{i}_IPRH ro (i=0..7) — Interrupt Pending Register High
  [31:0] REG
{0x2070+0x200*i} SHADOW_{i}_ICR wo (i=0..7) — Interrupt Clear Register
  [31:0] REG
{0x2074+0x200*i} SHADOW_{i}_ICRH wo (i=0..7) — Interrupt Clear Register High
  [31:0] REG
{0x2078+0x200*i} SHADOW_{i}_IEVAL access per field (i=0..7) — Interrupt Eval Register
  [0] EVAL wo — Interrupt Evaluate
    1=EVAL (Causes Region interrupt output to be pulsed is any enabled IERn and IPRn pending also masked by DRAEn)
{0x2080+0x200*i} SHADOW_{i}_QER ro (i=0..7) — QDMA Event Register
  [31:0] REG
{0x2084+0x200*i} SHADOW_{i}_QEER ro (i=0..7) — QDMA Event Enable Register
  [31:0] REG
{0x2088+0x200*i} SHADOW_{i}_QEECR wo (i=0..7) — QDMA Event Enable Clear Register
  [31:0] REG
{0x208C+0x200*i} SHADOW_{i}_QEESR wo (i=0..7) — QDMA Event Enable Set Register
  [31:0] REG
{0x2090+0x200*i} SHADOW_{i}_QSER ro (i=0..7) — QDMA Secondary Event Register
  [31:0] REG
{0x2094+0x200*i} SHADOW_{i}_QSECR wo (i=0..7) — QDMA Secondary Event Clear Register
  [31:0] REG
{0x4000+0x20*i} PARAMSET_{i}_OPT access per field (i=0..255) — Option
  [31] PRIV ro — Privilege level
    0=USER (User level privilege); 1=SUPERVISOR (Supervisor level privilege)
  [27:24] PRIVID ro — Privilege ID for external host/cpu/dma
  [23] ITCCHEN rw — Intermediate transfer completion chaining enable
    0=DISABLE (ITCC Disabled); 1=ENABLE (ITCC Enabled)
  [22] TCCHEN rw — Transfer completion chaining enable
    0=DISABLE (TCC Disabled); 1=ENABLE (TCC Enabled)
  [21] ITCINTEN rw — Intermediate transfer completion interrupt enable
    0=DISABLE; 1=ENABLE
  [20] TCINTEN rw — Transfer completion interrupt enable
    0=DISABLE; 1=ENABLE
  [17:12] TCC rw — Transfer completion code
  [11] TCCMODE rw — Transfer completion mode
    0=NORMAL; 1=EARLY
  [10:8] FWID rw — Fifo Width
    0=8; 1=16; 2=32; 3=64; 4=128; 5=256
  [3] STATIC rw — Static entry
    0=NORMAL; 1=STATIC
  [2] SYNCDIM rw — Transfer Synchronization Dimension
    0=ASYNC; 1=ABSYNC
  [1] DAM rw — Destination address mode
    0=INCR; 1=FIFO
  [0] SAM rw — Source address mode
    0=INCR; 1=FIFO
{0x4004+0x20*i} PARAMSET_{i}_SRC (i=0..255) — Source Address
{0x4008+0x20*i} PARAMSET_{i}_A_B_CNT (i=0..255) — A Count
  [31:16] BCNT — B Count
  [15:0] ACNT — A Count
{0x400C+0x20*i} PARAMSET_{i}_DST (i=0..255) — Destination Address
{0x4010+0x20*i} PARAMSET_{i}_SRC_DST_BIDX (i=0..255) — SRC B Index, DST B Index
  [31:16] DSTBIDX — Destination B Index
  [15:0] SRCBIDX — Source B Index
{0x4014+0x20*i} PARAMSET_{i}_LINK_BCNTRLD (i=0..255) — Link Address
  [31:16] BCNTRLD — B Count Reload
  [15:0] LINK — Link Address
{0x4018+0x20*i} PARAMSET_{i}_SRC_DST_CIDX (i=0..255) — Source C Index
  [31:16] DSTCIDX — Destination C Index
  [15:0] SRCCIDX — Source C Index
{0x401C+0x20*i} PARAMSET_{i}_CCNT (i=0..255) — C Count
  [15:0] CCNT — C Counter
